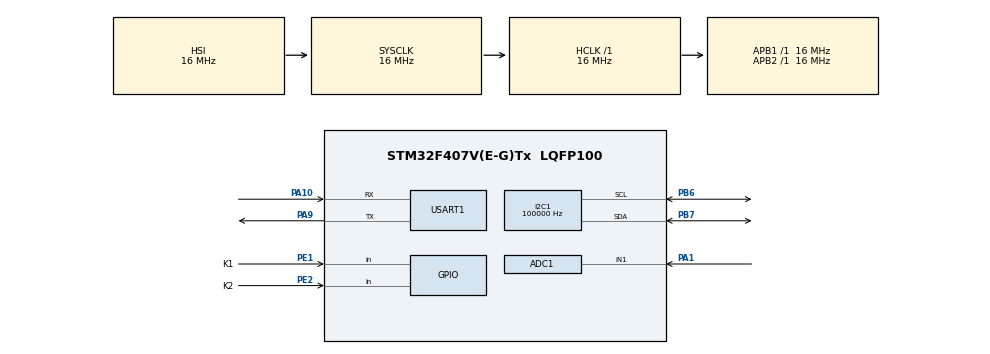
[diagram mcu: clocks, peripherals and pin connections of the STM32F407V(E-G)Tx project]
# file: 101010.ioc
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ADC1.Channel-3\#ChannelRegularConversion=ADC_CHANNEL_1
ADC1.ContinuousConvMode=ENABLE
ADC1.DMAContinuousRequests=ENABLE
ADC1.NbrOfConversionFlag=1
ADC1.Rank-3\#ChannelRegularConversion=1
ADC1.SamplingTime-3\#ChannelRegularConversion=ADC_SAMPLETIME_15CYCLES
ADC1.master=1
FREERTOS.Tasks01=defaultTask,24,256,StartDefaultTask,Default,NULL,Dynamic,NULL,NULL;TaskGUI,24,512,StartTaskGUI,Default,NULL,Dynamic,NULL,NULL;TaskKey,8,128,StartTaskKey,Default,NULL,Dynamic,NULL,NULL
I2C1.ClockSpeed=100000
Mcu.Family=STM32F4
Mcu.Name=STM32F407V(E-G)Tx
Mcu.Package=LQFP100
NVIC.PriorityGroup=NVIC_PRIORITYGROUP_4
NVIC.DMA2_Stream0_IRQn=true\:5\:0\:false\:false\:true\:true\:true\:true
NVIC.TIM7_IRQn=true\:15\:0\:false\:false\:true\:false\:true\:true
NVIC.TimeBase=TIM7_IRQn
NVIC.TimeBaseIP=TIM7
PA1.Signal=ADCx_IN1
PA10.Mode=Asynchronous
PA10.Signal=USART1_RX
PA13.Mode=Serial_Wire
PA13.Signal=SYS_JTMS-SWDIO
PA14.Mode=Serial_Wire
PA14.Signal=SYS_JTCK-SWCLK
PA9.Mode=Asynchronous
PA9.Signal=USART1_TX
PB6.Mode=I2C
PB6.Signal=I2C1_SCL
PB7.Mode=I2C
PB7.Signal=I2C1_SDA
PE1.GPIO_Label=K1
PE1.GPIO_PuPd=GPIO_PULLUP
PE1.Signal=GPIO_Input
PE2.GPIO_Label=K2
PE2.GPIO_PuPd=GPIO_PULLUP
PE2.Signal=GPIO_Input
PH0-OSC_IN.Mode=HSE-External-Oscillator
PH0-OSC_IN.Signal=RCC_OSC_IN
PH1-OSC_OUT.Mode=HSE-External-Oscillator
PH1-OSC_OUT.Signal=RCC_OSC_OUT
ProjectManager.HeapSize=0x200
ProjectManager.StackSize=0x400
ProjectManager.TargetToolchain=MDK-ARM V5.32
RCC.AHBFreq_Value=16000000
RCC.APB1Freq_Value=16000000
RCC.APB2Freq_Value=16000000
RCC.CortexFreq_Value=16000000
RCC.HSE_VALUE=25000000
RCC.HSI_VALUE=16000000
RCC.LSE_VALUE=32768
RCC.SYSCLKFreq_VALUE=16000000
RCC.VCOOutputFreq_Value=192000000
SH.ADCx_IN1.0=ADC1_IN1,IN1
USART1.VirtualMode=VM_ASYNC
VP_FREERTOS_VS_CMSIS_V2.Mode=CMSIS_V2
VP_SYS_VS_tim7.Mode=TIM7
board=custom

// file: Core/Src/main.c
/* USER CODE BEGIN Header */
/**
  ******************************************************************************
  * @file           : main.c
  * @brief          : Main program body
  ******************************************************************************
  * @attention
  *
  * Copyright (c) 2026 STMicroelectronics.
  * All rights reserved.
  *
  * This software is licensed under terms that can be found in the LICENSE file
  * in the root directory of this software component.
  * If no LICENSE file comes with this software, it is provided AS-IS.
  *
  ******************************************************************************
  */
/* USER CODE END Header */
#include "main.h"
#include "adc.h"
#include "dma.h"
#include "i2c.h"
#include "usart.h"
#include "gpio.h"
#include "cmsis_os2.h"
#include "app_freertos.h"

void SystemClock_Config(void);

int main(void)
{

  /* MCU Configuration--------------------------------------------------------*/

  /* Reset of all peripherals, Initializes the Flash interface and the Systick. */
  HAL_Init();

  /* Configure the system clock */
  SystemClock_Config();

  /* Initialize all configured peripherals */
  MX_GPIO_Init();
  MX_DMA_Init();
  MX_ADC1_Init();
  MX_I2C1_Init();
  MX_USART1_UART_Init();
  /* USER CODE BEGIN 2 */
  osKernelInitialize();
  MX_FREERTOS_Init();
  osKernelStart();

  /* USER CODE END 2 */

  /* Infinite loop */
  while (1)
  {

  }
}

void SystemClock_Config(void)
{
  RCC_OscInitTypeDef RCC_OscInitStruct = {0};
  RCC_ClkInitTypeDef RCC_ClkInitStruct = {0};

  /** Configure the main internal regulator output voltage
  */
  __HAL_RCC_PWR_CLK_ENABLE();
  __HAL_PWR_VOLTAGESCALING_CONFIG(PWR_REGULATOR_VOLTAGE_SCALE1);

  /** Initializes the RCC Oscillators according to the specified parameters
  * in the RCC_OscInitTypeDef structure.
  */
  RCC_OscInitStruct.OscillatorType = RCC_OSCILLATORTYPE_HSI;
  RCC_OscInitStruct.HSIState = RCC_HSI_ON;
  RCC_OscInitStruct.HSICalibrationValue = RCC_HSICALIBRATION_DEFAULT;
  RCC_OscInitStruct.PLL.PLLState = RCC_PLL_NONE;
  if (HAL_RCC_OscConfig(&RCC_OscInitStruct) != HAL_OK)
  {
    Error_Handler();
  }

  /** Initializes the CPU, AHB and APB buses clocks
  */
  RCC_ClkInitStruct.ClockType = RCC_CLOCKTYPE_HCLK|RCC_CLOCKTYPE_SYSCLK
                              |RCC_CLOCKTYPE_PCLK1|RCC_CLOCKTYPE_PCLK2;
  RCC_ClkInitStruct.SYSCLKSource = RCC_SYSCLKSOURCE_HSI;
  RCC_ClkInitStruct.AHBCLKDivider = RCC_SYSCLK_DIV1;
  RCC_ClkInitStruct.APB1CLKDivider = RCC_HCLK_DIV1;
  RCC_ClkInitStruct.APB2CLKDivider = RCC_HCLK_DIV1;

  if (HAL_RCC_ClockConfig(&RCC_ClkInitStruct, FLASH_LATENCY_0) != HAL_OK)
  {
    Error_Handler();
  }
}

void HAL_TIM_PeriodElapsedCallback(TIM_HandleTypeDef *htim)
{
  if (htim->Instance == TIM7)
  {
    HAL_IncTick();
  }
}

void Error_Handler(void)
{
  __disable_irq();
  while (1)
  {
  }
}

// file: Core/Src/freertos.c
#include "FreeRTOS.h"
#include "task.h"
#include "cmsis_os2.h"
#include "main.h"
#include "adc.h"
#include "usart.h"
#include "GUI.h"
#include <stdio.h>

#define ADC_BUF_SIZE 128U
#define ENABLE_USART_DEBUG 0

typedef enum {
  PAGE_LOGO = 0,
  PAGE_NAME,
  PAGE_MAIN
} PageType;

extern GUI_FLASH const GUI_FONT GUI_FontHZ_Info_16;
extern GUI_FLASH const GUI_FONT GUI_FontHZ_AdLabel_16;
extern GUI_FLASH const GUI_BITMAP bmHduLogo;

volatile PageType g_current_page = PAGE_LOGO;
volatile uint16_t g_ad_value = 0;
volatile uint8_t g_curve_data[128];
volatile uint8_t g_curve_ready = 0;
volatile uint8_t g_adc_running = 0;

static uint16_t adc_buf[ADC_BUF_SIZE];
static uint32_t page_enter_tick = 0;

osThreadId_t defaultTaskHandle;
osThreadId_t taskGUIHandle;
osThreadId_t taskKeyHandle;

const osThreadAttr_t defaultTask_attributes = {
  .name = "defaultTask",
  .stack_size = 256 * 4,
  .priority = (osPriority_t) osPriorityNormal,
};

const osThreadAttr_t taskGUI_attributes = {
  .name = "TaskGUI",
  .stack_size = 512 * 4,
  .priority = (osPriority_t) osPriorityNormal,
};

const osThreadAttr_t taskKey_attributes = {
  .name = "TaskKey",
  .stack_size = 128 * 4,
  .priority = (osPriority_t) osPriorityBelowNormal,
};

static void StartDefaultTask(void *argument);
static void StartTaskGUI(void *argument);
static void StartTaskKey(void *argument);
static void DrawPageLogo(void);
static void DrawPageName(void);
static void DrawPageMain(void);
static void SetPage(PageType page);
static uint8_t KeyPressed(GPIO_TypeDef *port, uint16_t pin);

void MX_FREERTOS_Init(void)
{
  defaultTaskHandle = osThreadNew(StartDefaultTask, NULL, &defaultTask_attributes);
  taskGUIHandle = osThreadNew(StartTaskGUI, NULL, &taskGUI_attributes);
  taskKeyHandle = osThreadNew(StartTaskKey, NULL, &taskKey_attributes);
}

static void StartDefaultTask(void *argument)
{
  (void)argument;

  g_adc_running = (HAL_ADC_Start_DMA(&hadc1, (uint32_t *)adc_buf, ADC_BUF_SIZE) == HAL_OK);

  for (;;)
  {
#if ENABLE_USART_DEBUG
    printf("AD:%u\r\n", g_ad_value);
#endif
    osDelay(200);
  }
}

static void StartTaskGUI(void *argument)
{
  (void)argument;

  GUI_Init();
  GUI_SetColor(GUI_COLOR_WHITE);
  SetPage(PAGE_LOGO);

  for (;;)
  {
    switch (g_current_page)
    {
      case PAGE_LOGO:
        DrawPageLogo();
        break;
      case PAGE_NAME:
        DrawPageName();
        break;
      case PAGE_MAIN:
      default:
        DrawPageMain();
        break;
    }
    GUI_Update();
    osDelay(50);
  }
}

static void StartTaskKey(void *argument)
{
  (void)argument;

  for (;;)
  {
    if (KeyPressed(K1_GPIO_Port, K1_Pin))
    {
      SetPage(PAGE_LOGO);
    }

    if (KeyPressed(K2_GPIO_Port, K2_Pin))
    {
      SetPage(PAGE_MAIN);
    }

    osDelay(20);
  }
}

static void DrawPageLogo(void)
{
  GUI_Clear();
  GUI_DrawBitmap(&bmHduLogo, 32, 0);

  if (osKernelGetTickCount() - page_enter_tick >= 3000U)
  {
    SetPage(PAGE_NAME);
  }
}

static void DrawPageName(void)
{
  GUI_Clear();
  GUI_SetFont(&GUI_FontHZ_Info_16);
  GUI_DispStringHCenterAt("Author", 64, 8);
  GUI_SetFont(GUI_DEFAULT_FONT);
  GUI_DispStringHCenterAt("Exp9 Audio Curve", 64, 34);
  GUI_DispStringHCenterAt("Demo ID", 64, 48);

  if (osKernelGetTickCount() - page_enter_tick >= 2000U)
  {
    SetPage(PAGE_MAIN);
  }
}

static void DrawPageMain(void)
{
  char buf[24];
  uint8_t curve[128];

  GUI_Clear();
  GUI_SetFont(&GUI_FontHZ_AdLabel_16);
  GUI_DispStringAt("\345\275\223\345\211\215", 0, 0);
  GUI_DispStringAt("\345\200\274", 50, 0);
  GUI_SetFont(GUI_DEFAULT_FONT);
  GUI_DispStringAt("AD", 34, 4);
  sprintf(buf, ":%4u", g_ad_value);
  GUI_DispStringAt(buf, 66, 4);
  GUI_DrawLine(0, 17, 127, 17);

  if (g_curve_ready)
  {
    for (uint32_t i = 0; i < 128U; ++i)
    {
      curve[i] = g_curve_data[i];
    }

    for (uint32_t i = 0; i < 127U; ++i)
    {
      int y1 = 63 - ((int)curve[i] * 45 / 255);
      int y2 = 63 - ((int)curve[i + 1U] * 45 / 255);
      GUI_DrawLine((int)i, y1, (int)i + 1, y2);
    }
  }
}

static void SetPage(PageType page)
{
  g_current_page = page;
  page_enter_tick = osKernelGetTickCount();
}

static uint8_t KeyPressed(GPIO_TypeDef *port, uint16_t pin)
{
  if (HAL_GPIO_ReadPin(port, pin) == GPIO_PIN_RESET)
  {
    osDelay(20);
    if (HAL_GPIO_ReadPin(port, pin) == GPIO_PIN_RESET)
    {
      while (HAL_GPIO_ReadPin(port, pin) == GPIO_PIN_RESET)
      {
        osDelay(10);
      }
      return 1U;
    }
  }
  return 0U;
}

void HAL_ADC_ConvCpltCallback(ADC_HandleTypeDef *hadc)
{
  uint32_t sum = 0;

  if (hadc->Instance != ADC1)
  {
    return;
  }

  for (uint32_t i = 0; i < ADC_BUF_SIZE; ++i)
  {
    uint16_t value = adc_buf[i] & 0x0FFFU;
    sum += value;
    g_curve_data[i] = (uint8_t)(value >> 4);
  }

  g_ad_value = (uint16_t)(sum / ADC_BUF_SIZE);
  g_curve_ready = 1U;
}

int fputc(int ch, FILE *f)
{
  (void)f;
  HAL_UART_Transmit(&huart1, (uint8_t *)&ch, 1, 10);
  return ch;
}
